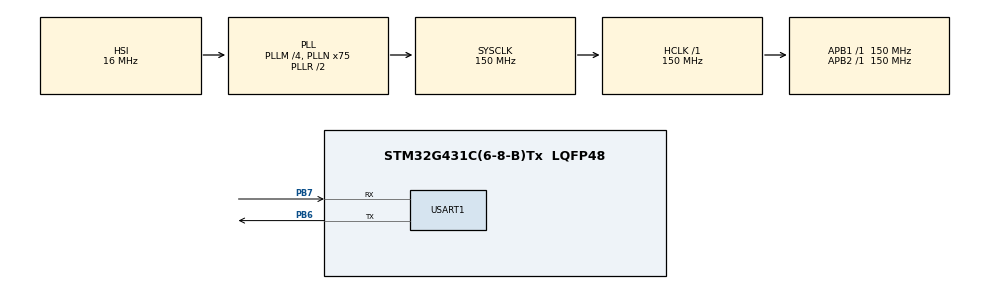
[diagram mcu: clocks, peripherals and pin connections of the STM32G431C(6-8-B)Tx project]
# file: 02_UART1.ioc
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Mcu.Family=STM32G4
Mcu.Name=STM32G431C(6-8-B)Tx
Mcu.Package=LQFP48
NVIC.PriorityGroup=NVIC_PRIORITYGROUP_4
NVIC.USART1_IRQn=true\:0\:0\:false\:false\:true\:true\:true\:true
PA13.Mode=Serial_Wire
PA13.Signal=SYS_JTMS-SWDIO
PA14.Mode=Serial_Wire
PA14.Signal=SYS_JTCK-SWCLK
PB6.Mode=Asynchronous
PB6.Signal=USART1_TX
PB7.GPIO_PuPd=GPIO_PULLUP
PB7.Mode=Asynchronous
PB7.Signal=USART1_RX
PF0-OSC_IN.Mode=HSE-External-Clock-Source
PF0-OSC_IN.Signal=RCC_OSC_IN
ProjectManager.HeapSize=0x200
ProjectManager.StackSize=0x400
ProjectManager.TargetToolchain=STM32CubeIDE
RCC.ADC12Freq_Value=150000000
RCC.AHBFreq_Value=150000000
RCC.APB1Freq_Value=150000000
RCC.APB1TimFreq_Value=150000000
RCC.APB2Freq_Value=150000000
RCC.APB2TimFreq_Value=150000000
RCC.CortexFreq_Value=150000000
RCC.EXTERNAL_CLOCK_VALUE=12288000
RCC.HCLKFreq_Value=150000000
RCC.HSE_VALUE=8000000
RCC.HSI48_VALUE=48000000
RCC.HSI_VALUE=16000000
RCC.LSE_VALUE=32768
RCC.PLLM=RCC_PLLM_DIV4
RCC.PLLN=75
RCC.SYSCLKFreq_VALUE=150000000
RCC.SYSCLKSource=RCC_SYSCLKSOURCE_PLLCLK
RCC.USBFreq_Value=150000000
RCC.VCOOutputFreq_Value=300000000
USART1.VirtualMode-Asynchronous=VM_ASYNC
board=custom

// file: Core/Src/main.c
/* USER CODE BEGIN Header */
/**
  ******************************************************************************
  * @file           : main.c
  * @brief          : Main program body
  ******************************************************************************
  * @attention
  *
  * Copyright (c) 2024 STMicroelectronics.
  * All rights reserved.
  *
  * This software is licensed under terms that can be found in the LICENSE file
  * in the root directory of this software component.
  * If no LICENSE file comes with this software, it is provided AS-IS.
  *
  ******************************************************************************
  */
/* USER CODE END Header */
#include "main.h"

/* USER CODE BEGIN Includes */
 #include <stdio.h>
/* USER CODE END Includes */

UART_HandleTypeDef huart1;

void SystemClock_Config(void);
static void MX_GPIO_Init(void);
static void MX_USART1_UART_Init(void);
/* USER CODE BEGIN PFP */
int __io_putchar(int ch)
{
	if(HAL_UART_Transmit(&huart1, (uint8_t *)&ch, 1, 10) != HAL_OK)
	{
		return -1;
	}
	return ch;
}
/* USER CODE END PFP */

/* USER CODE BEGIN 0 */
uint8_t rxbuf;
void HAL_UART_RxCpltCallback(UART_HandleTypeDef *huart)
{
  if (huart->Instance == USART1)
  {
	  HAL_UART_Transmit(&huart1, (uint8_t *)&rxbuf, 1, 10);
	  HAL_UART_Receive_IT(huart, &rxbuf, 1);
  }
}
/* USER CODE END 0 */

int main(void)
{

  /* MCU Configuration--------------------------------------------------------*/

  /* Reset of all peripherals, Initializes the Flash interface and the Systick. */
  HAL_Init();

  /* Configure the system clock */
  SystemClock_Config();

  /* Initialize all configured peripherals */
  MX_GPIO_Init();
  MX_USART1_UART_Init();
  /* USER CODE BEGIN 2 */
  printf("hello uart\r\n");
  HAL_UART_Receive_IT(&huart1, &rxbuf, 1);
  /* USER CODE END 2 */

  /* Infinite loop */
  while (1)
  {

  }
}

void SystemClock_Config(void)
{
  RCC_OscInitTypeDef RCC_OscInitStruct = {0};
  RCC_ClkInitTypeDef RCC_ClkInitStruct = {0};

  /** Configure the main internal regulator output voltage
  */
  HAL_PWREx_ControlVoltageScaling(PWR_REGULATOR_VOLTAGE_SCALE1);

  /** Initializes the RCC Oscillators according to the specified parameters
  * in the RCC_OscInitTypeDef structure.
  */
  RCC_OscInitStruct.OscillatorType = RCC_OSCILLATORTYPE_HSI;
  RCC_OscInitStruct.HSIState = RCC_HSI_ON;
  RCC_OscInitStruct.HSICalibrationValue = RCC_HSICALIBRATION_DEFAULT;
  RCC_OscInitStruct.PLL.PLLState = RCC_PLL_ON;
  RCC_OscInitStruct.PLL.PLLSource = RCC_PLLSOURCE_HSI;
  RCC_OscInitStruct.PLL.PLLM = RCC_PLLM_DIV4;
  RCC_OscInitStruct.PLL.PLLN = 75;
  RCC_OscInitStruct.PLL.PLLP = RCC_PLLP_DIV2;
  RCC_OscInitStruct.PLL.PLLQ = RCC_PLLQ_DIV2;
  RCC_OscInitStruct.PLL.PLLR = RCC_PLLR_DIV2;
  if (HAL_RCC_OscConfig(&RCC_OscInitStruct) != HAL_OK)
  {
    Error_Handler();
  }

  /** Initializes the CPU, AHB and APB buses clocks
  */
  RCC_ClkInitStruct.ClockType = RCC_CLOCKTYPE_HCLK|RCC_CLOCKTYPE_SYSCLK
                              |RCC_CLOCKTYPE_PCLK1|RCC_CLOCKTYPE_PCLK2;
  RCC_ClkInitStruct.SYSCLKSource = RCC_SYSCLKSOURCE_PLLCLK;
  RCC_ClkInitStruct.AHBCLKDivider = RCC_SYSCLK_DIV1;
  RCC_ClkInitStruct.APB1CLKDivider = RCC_HCLK_DIV1;
  RCC_ClkInitStruct.APB2CLKDivider = RCC_HCLK_DIV1;

  if (HAL_RCC_ClockConfig(&RCC_ClkInitStruct, FLASH_LATENCY_4) != HAL_OK)
  {
    Error_Handler();
  }
}

static void MX_USART1_UART_Init(void)
{

  huart1.Instance = USART1;
  huart1.Init.BaudRate = 115200;
  huart1.Init.WordLength = UART_WORDLENGTH_8B;
  huart1.Init.StopBits = UART_STOPBITS_1;
  huart1.Init.Parity = UART_PARITY_NONE;
  huart1.Init.Mode = UART_MODE_TX_RX;
  huart1.Init.HwFlowCtl = UART_HWCONTROL_NONE;
  huart1.Init.OverSampling = UART_OVERSAMPLING_16;
  huart1.Init.OneBitSampling = UART_ONE_BIT_SAMPLE_DISABLE;
  huart1.Init.ClockPrescaler = UART_PRESCALER_DIV1;
  huart1.AdvancedInit.AdvFeatureInit = UART_ADVFEATURE_NO_INIT;
  if (HAL_UART_Init(&huart1) != HAL_OK)
  {
    Error_Handler();
  }
  if (HAL_UARTEx_SetTxFifoThreshold(&huart1, UART_TXFIFO_THRESHOLD_1_8) != HAL_OK)
  {
    Error_Handler();
  }
  if (HAL_UARTEx_SetRxFifoThreshold(&huart1, UART_RXFIFO_THRESHOLD_1_8) != HAL_OK)
  {
    Error_Handler();
  }
  if (HAL_UARTEx_DisableFifoMode(&huart1) != HAL_OK)
  {
    Error_Handler();
  }

}

static void MX_GPIO_Init(void)
{

  /* GPIO Ports Clock Enable */
  __HAL_RCC_GPIOF_CLK_ENABLE();
  __HAL_RCC_GPIOA_CLK_ENABLE();
  __HAL_RCC_GPIOB_CLK_ENABLE();

}

void Error_Handler(void)
{
  __disable_irq();
  while (1)
  {
  }
}
